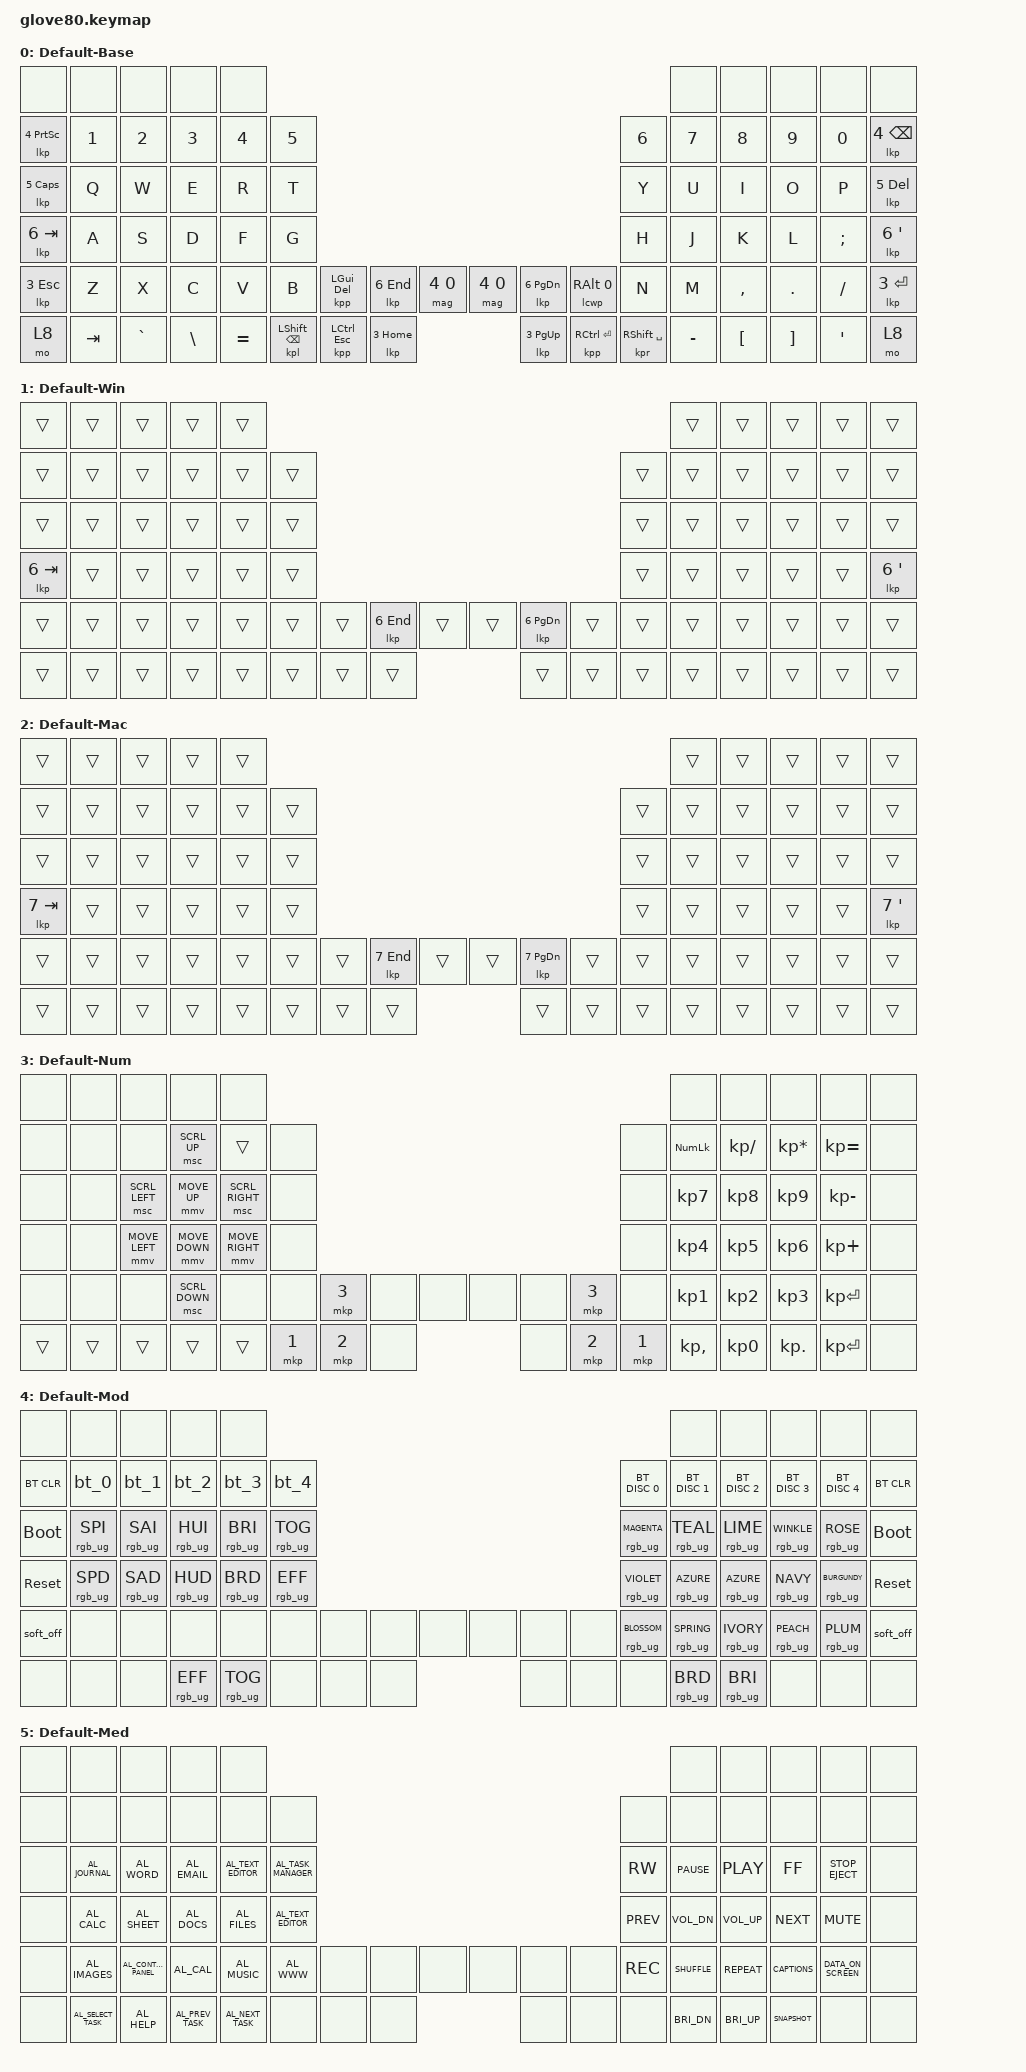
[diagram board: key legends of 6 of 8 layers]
#define ZMK_POINTING_DEFAULT_MOVE_VAL 1400  // default: 600
#define ZMK_POINTING_DEFAULT_SCRL_VAL 40    // default: 10
#define USER_CONFIG_DEFAULT_KEYMAP 1        // default: keymaps

/*
 * Copyright (c) 2020 The ZMK Contributors
 *
 * SPDX-License-Identifier: MIT
 */
#include <behaviors.dtsi>
#include <dt-bindings/zmk/backlight.h>
#include <dt-bindings/zmk/bt.h>
#include <dt-bindings/zmk/ext_power.h>
#include <dt-bindings/zmk/keys.h>
#include <dt-bindings/zmk/outputs.h>
#include <dt-bindings/zmk/pointing.h>
#include <dt-bindings/zmk/rgb.h>
#include "plugin/overrides.dtsi"
#include "colors.dtsi"
#include "keys.dtsi"

#define MAGIC(ID, FIRST, SECOND, TERM) \
    ID: mag_tap_##ID { \
        compatible = "zmk,behavior-hold-tap"; \
        label = "MAGIC_HOLD_TAP"; \
        flavor = "tap-preferred"; \
        tapping-term-ms = <TERM>; \
        #binding-cells = <2>; \
        bindings = <&FIRST>, <&SECOND>; \
    };

/ {
    behaviors {
        #include "plugin/definitions.dtsi"
        #include "plugin/declarations.dtsi"
        #include "plugin/macros.dtsi"
        #include "version.dtsi"
        #include "combos.dtsi"
        #include "macros.dtsi"

        MAGIC(mag, mo, rgb_ug_status_macro, 185)
    };

    keymap {
        compatible = "zmk,keymap";

        default_layer {
            display-name = "Default-Base";
            bindings = <
                &none         &none   &none  &none &none                                                                                                                  &none     &none      &none       &none     &none
                &lkp  4 PSCRN &kp N1  &kp N2  &kp N3 &kp N4     &kp N5                                                                                            &kp N6  &kp N7    &kp N8     &kp N9      &kp N0    &lkp 4 BSPC
                &lkp  5 CAPS  &kp Q   &kp W   &kp E  &kp R      &kp T                                                                                             &kp Y   &kp U     &kp I      &kp O       &kp P     &lkp 5 DEL
                &lkp  6 TAB   &kp A   &kp S   &kp D  &kp F      &kp G                                                                                             &kp H   &kp J     &kp K      &kp L       &kp SEMI  &lkp 6 SQT
                &lkp  3 ESC   &kp Z   &kp X   &kp C  &kp V      &kp B   &kpp LGUI DEL   &lkp 6 END     &mag 4 0    &mag 4 0     &lkp 6 PG_DN     &lcwp RALT 0     &kp N   &kp M     &kp COMMA  &kp DOT     &kp FSLH  &lkp 3 ENTER
                &mo   8       &kp TAB &kp GRAVE &kp BSLH  &kp EQUAL     &kpl LSHFT BSPC &kpp LCTRL ESC &lkp 3 HOME &lkp 3 PG_UP &kpp RCTRL ENTER &kpr RSHFT SPACE         &kp MINUS &kp LBKT   &kp RBKT    &kp SQT   &mo 8
            >;
        };
        default_win {
            display-name = "Default-Win";
            bindings = <
                &trans       &trans  &trans  &trans  &trans                                                                               &trans  &trans  &trans   &trans    &trans
                &trans       &trans  &trans  &trans  &trans   &trans                                                              &trans  &trans  &trans  &trans   &trans    &trans
                &trans       &trans  &trans  &trans  &trans   &trans                                                              &trans  &trans  &trans  &trans   &trans    &trans
                &lkp 6 TAB   &trans  &trans  &trans  &trans   &trans                                                              &trans  &trans  &trans  &trans   &trans    &lkp 6 SQT
                &trans       &trans  &trans  &trans  &trans   &trans   &trans &lkp 6 END    &trans &trans &lkp 6 PG_DN &trans     &trans  &trans  &trans  &trans   &trans    &trans
                &trans       &trans  &trans  &trans  &trans            &trans &trans        &trans &trans &trans       &trans             &trans  &trans  &trans   &trans    &trans
            >;
        };
        default_mac {
            display-name = "Default-Mac";
            bindings = <
                &trans       &trans  &trans  &trans  &trans                                                                               &trans  &trans  &trans   &trans    &trans
                &trans       &trans  &trans  &trans  &trans   &trans                                                              &trans  &trans  &trans  &trans   &trans    &trans
                &trans       &trans  &trans  &trans  &trans   &trans                                                              &trans  &trans  &trans  &trans   &trans    &trans
                &lkp 7 TAB   &trans  &trans  &trans  &trans   &trans                                                              &trans  &trans  &trans  &trans   &trans    &lkp 7 SQT
                &trans       &trans  &trans  &trans  &trans   &trans   &trans &lkp 7 END    &trans &trans &lkp 7 PG_DN &trans     &trans  &trans  &trans  &trans   &trans    &trans
                &trans       &trans  &trans  &trans  &trans            &trans &trans        &trans &trans &trans       &trans             &trans  &trans  &trans   &trans    &trans
            >;
        };
        deafult_num {
            display-name = "Default-Num";
            bindings = <
                &none  &none  &none          &none           &none                                                                         &none          &none           &none           &none         &none
                &none  &none  &none          &msc SCRL_UP    &trans          &none                                                   &none &kp KP_NUM     &kp KP_DIVIDE   &kp KP_MULTIPLY &kp KP_EQUAL  &none
                &none  &none  &msc SCRL_LEFT &mmv MOVE_UP    &msc SCRL_RIGHT &none                                                   &none &kp KP_N7      &kp KP_N8       &kp KP_N9       &kp KP_MINUS  &none
                &none  &none  &mmv MOVE_LEFT &mmv MOVE_DOWN  &mmv MOVE_RIGHT &none                                                   &none &kp KP_N4      &kp KP_N5       &kp KP_N6       &kp KP_PLUS   &none
                &none  &none  &none          &msc SCRL_DOWN  &none           &none     &mkp 3 &none  &none  &none &none  &mkp 3      &none &kp KP_N1      &kp KP_N2       &kp KP_N3       &kp KP_ENTER  &none
                &trans &trans &trans         &trans  &trans                            &mkp 1 &mkp 2 &none  &none &mkp 2 &mkp 1            &kp KP_COMMA   &kp KP_NUMBER_0 &kp KP_DOT      &kp KP_ENTER  &none
            >;
        };
        default_mod {
            display-name = "Default-Mod";
            bindings = <
                &none       &none            &none           &none           &none                                                                                &none          &none           &none          &none            &none
                &bt BT_CLR  &bt_0            &bt_1           &bt_2           &bt_3           &bt_4                                                &bt BT_DISC 0   &bt BT_DISC 1  &bt BT_DISC 2 &bt BT_DISC 3  &bt BT_DISC 4    &bt BT_CLR
                &bootloader &rgb_ug RGB_SPI  &rgb_ug RGB_SAI &rgb_ug RGB_HUI &rgb_ug RGB_BRI &rgb_ug RGB_TOG                                      &rgb_ug MAGENTA &rgb_ug TEAL   &rgb_ug LIME  &rgb_ug WINKLE &rgb_ug ROSE     &bootloader
                &sys_reset  &rgb_ug RGB_SPD  &rgb_ug RGB_SAD &rgb_ug RGB_HUD &rgb_ug RGB_BRD &rgb_ug RGB_EFF                                      &rgb_ug VIOLET  &rgb_ug AZURE  &rgb_ug AZURE &rgb_ug NAVY   &rgb_ug BURGUNDY &sys_reset
                &soft_off   &none            &none           &none           &none           &none           &none &none &none &none &none &none  &rgb_ug BLOSSOM &rgb_ug SPRING &rgb_ug IVORY &rgb_ug PEACH  &rgb_ug PLUM     &soft_off
                &none       &none            &none           &rgb_ug RGB_EFF &rgb_ug RGB_TOG                 &none &none &none &none &none &none                  &rgb_ug RGB_BRD &rgb_ug RGB_BRI &none       &none            &none
            >;
        };
        deafult_med {
            display-name = "Default-Med";
            bindings = <
                &none &none            &none          &none           &none                                                                                            &none          &none         &none          &none                &none
                &none &none             &none         &none           &none                 &none                                                         &none        &none          &none         &none          &none                &none
                &none &kp C_AL_JOURNAL  &kp C_AL_WORD &kp C_AL_EMAIL  &kp C_AL_TEXT_EDITOR  &kp C_AL_TASK_MANAGER                                         &kp C_RW     &kp C_PAUSE    &kp C_PLAY    &kp C_FF       &kp C_STOP_EJECT     &none
                &none &kp C_AL_CALC     &kp C_AL_SHEET &kp C_AL_DOCS  &kp C_AL_FILES        &kp C_AL_TEXT_EDITOR                                          &kp C_PREV   &kp C_VOL_DN   &kp C_VOL_UP  &kp C_NEXT     &kp C_MUTE           &none
                &none &kp C_AL_IMAGES   &kp C_AL_CONTROL_PANEL &kp C_AL_CAL &kp C_AL_MUSIC  &kp C_AL_WWW           &none &none &none &none &none &none    &kp C_REC    &kp C_SHUFFLE  &kp C_REPEAT  &kp C_CAPTIONS &kp C_DATA_ON_SCREEN &none
                &none &kp C_AL_SELECT_TASK &kp C_AL_HELP  &kp C_AL_PREV_TASK &kp C_AL_NEXT_TASK                    &none &none &none &none &none &none                 &kp C_BRI_DN   &kp C_BRI_UP  &kp C_SNAPSHOT &none                &none
            >;
        };
        win_nav {
            display-name = "Windows-Nav";
            bindings = <
                &trans         &trans               &trans           &trans            &trans        &trans  &trans  &trans  &trans  &trans  &trans  &trans  &trans        &trans         &trans         &trans         &trans                &trans
                &kp F11        &kp F1               &kp F2           &kp F3            &kp F4        &kp F5                                                  &kp F6        &kp F7         &kp F8         &kp F9         &kp F10               &kp F12
                &mac_backtick  &kp LA(F4)           &win_select_word &win_select_to_end &kp LC(BSPC)  &kp LC(HOME)                                            &kp RC(LEFT) &kp RC(DOWN)   &kp RC(UP)     &kp RC(RIGHT)  &win_select_pgph      &win_block
                &mac_quotes    &win_select_to_start &win_select_line &win_kill_line    &kp LC(DEL)   &kp LC(A)                                               &kp LEFT      &kp DOWN       &kp UP         &kp RIGHT      &win_select_doc_start &mac_dquotes
                &mac_parens    &win_undo            &win_cut         &win_copy         &win_paste    &kp LC(END)                                             &kp HOME      &kp PG_DN      &kp PG_UP      &kp END        &win_select_doc_end   &mac_braces
                               &none                &mac_fatarrow    &win_join_pln     &win_join_nln                                                                       &win_open_dln  &win_open_uln  &mac_arrow     &none
                                                                                                                    &trans  &trans  &trans  &trans
                                                                                                                            &trans  &trans
                                                                                                             &trans &trans  &trans  &trans  &trans &trans
                                                                                                                       &trans   &trans   &trans
            >;
        };
        mac_nav {
            display-name = "Nav-mac";
            bindings = <
                &trans         &trans               &trans           &trans            &trans        &trans  &trans  &trans  &trans  &trans  &trans  &trans  &trans       &trans         &trans         &trans         &trans                &trans
                &kp F11        &kp F1               &kp F2           &kp F3            &kp F4        &kp F5                                                  &kp F6       &kp F7         &kp F8         &kp F9         &kp F10               &kp F12
                &mac_backtick  &kp LG(Q)            &mac_select_word &mac_select_to_end &kp LA(BSPC) &kp LG(UP)                                              &kp RA(LEFT) &kp RA(DOWN)   &kp RA(UP)     &kp RA(RIGHT)  &mac_select_pgph      &mac_block
                &mac_quotes    &mac_select_to_start &mac_select_line &mac_kill_line    &kp LA(DEL)   &kp LG(A)                                               &kp LEFT     &kp DOWN       &kp UP         &kp RIGHT      &mac_select_doc_start &mac_dquotes
                &mac_parens    &mac_undo            &mac_cut         &mac_copy         &mac_paste    &kp LG(DOWN)                                            &kp RG(LEFT) &kp PG_DN      &kp PG_UP      &kp RG(RIGHT)  &mac_select_doc_end   &mac_braces
                               &none                &mac_fatarrow    &mac_join_pln     &mac_join_nln                                                                      &mac_open_dln  &mac_open_uln  &mac_arrow     &none
                                                                                                                    &trans  &trans  &trans  &trans
                                                                                                                            &trans  &trans
                                                                                                             &trans &trans  &trans  &trans  &trans &trans
                                                                                                                       &trans   &trans   &trans
            >;
        };
    };
};
